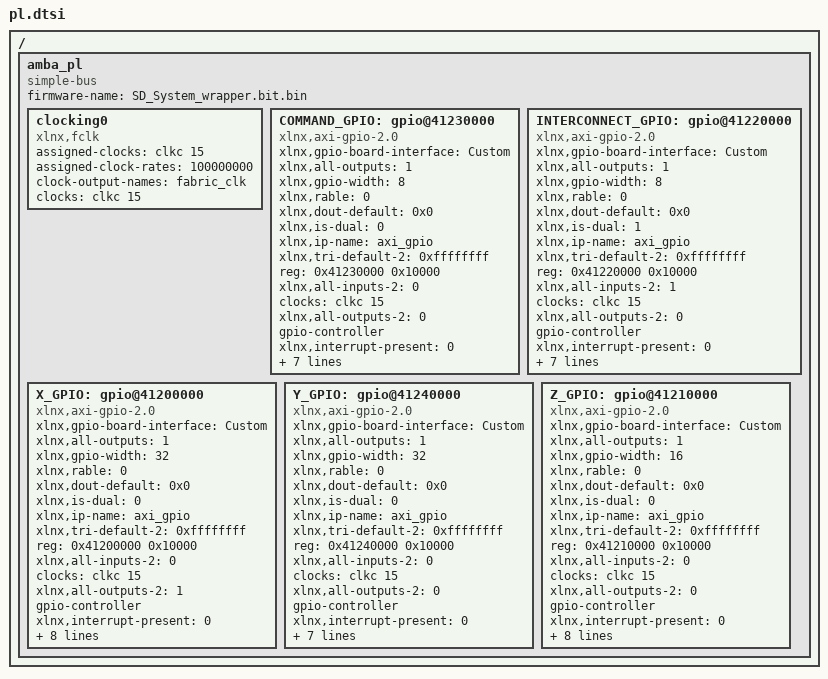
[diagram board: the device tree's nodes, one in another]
/ {
	amba_pl: amba_pl {
		ranges;
		compatible = "simple-bus";
		#address-cells = <1>;
		#size-cells = <1>;
		firmware-name = "SD_System_wrapper.bit.bin";
		clocking0: clocking0 {
			compatible = "xlnx,fclk";
			assigned-clocks = <&clkc 15>;
			assigned-clock-rates = <100000000>;
			#clock-cells = <0>;
			clock-output-names = "fabric_clk";
			clocks = <&clkc 15>;
		};
		COMMAND_GPIO: gpio@41230000 {
			xlnx,gpio-board-interface = "Custom";
			compatible = "xlnx,axi-gpio-2.0" , "xlnx,xps-gpio-1.00.a";
			xlnx,all-outputs = <1>;
			#gpio-cells = <2>;
			xlnx,gpio-width = <8>;
			xlnx,rable = <0>;
			xlnx,dout-default = <0x0>;
			xlnx,is-dual = <0>;
			xlnx,ip-name = "axi_gpio";
			xlnx,tri-default-2 = <0xffffffff>;
			reg = <0x41230000 0x10000>;
			xlnx,all-inputs-2 = <0>;
			clocks = <&clkc 15>;
			xlnx,all-outputs-2 = <0>;
			gpio-controller;
			xlnx,interrupt-present = <0>;
			xlnx,gpio2-board-interface = "Custom";
			xlnx,edk-iptype = "PERIPHERAL";
			xlnx,dout-default-2 = <0x0>;
			status = "okay";
			xlnx,gpio2-width = <32>;
			clock-names = "s_axi_aclk";
			xlnx,tri-default = <0xffffffff>;
			xlnx,name = "COMMAND_GPIO";
			xlnx,all-inputs = <0>;
		};
		INTERCONNECT_GPIO: gpio@41220000 {
			xlnx,gpio-board-interface = "Custom";
			compatible = "xlnx,axi-gpio-2.0" , "xlnx,xps-gpio-1.00.a";
			xlnx,all-outputs = <1>;
			#gpio-cells = <2>;
			xlnx,gpio-width = <8>;
			xlnx,rable = <0>;
			xlnx,dout-default = <0x0>;
			xlnx,is-dual = <1>;
			xlnx,ip-name = "axi_gpio";
			xlnx,tri-default-2 = <0xffffffff>;
			reg = <0x41220000 0x10000>;
			xlnx,all-inputs-2 = <1>;
			clocks = <&clkc 15>;
			xlnx,all-outputs-2 = <0>;
			gpio-controller;
			xlnx,interrupt-present = <0>;
			xlnx,gpio2-board-interface = "Custom";
			xlnx,edk-iptype = "PERIPHERAL";
			xlnx,dout-default-2 = <0x0>;
			status = "okay";
			xlnx,gpio2-width = <8>;
			clock-names = "s_axi_aclk";
			xlnx,tri-default = <0xffffffff>;
			xlnx,name = "INTERCONNECT_GPIO";
			xlnx,all-inputs = <0>;
		};
		X_GPIO: gpio@41200000 {
			xlnx,gpio-board-interface = "Custom";
			compatible = "xlnx,axi-gpio-2.0" , "xlnx,xps-gpio-1.00.a";
			xlnx,all-outputs = <1>;
			#gpio-cells = <2>;
			xlnx,gpio-width = <32>;
			xlnx,rable = <0>;
			xlnx,dout-default = <0x0>;
			xlnx,is-dual = <0>;
			xlnx,ip-name = "axi_gpio";
			xlnx,tri-default-2 = <0xffffffff>;
			reg = <0x41200000 0x10000>;
			xlnx,all-inputs-2 = <0>;
			clocks = <&clkc 15>;
			xlnx,all-outputs-2 = <1>;
			gpio-controller;
			xlnx,interrupt-present = <0>;
			xlnx,gpio2-board-interface = "Custom";
			xlnx,edk-iptype = "PERIPHERAL";
			xlnx,dout-default-2 = <0x0>;
			status = "okay";
			xlnx,gpio2-width = <32>;
			clock-names = "s_axi_aclk";
			xlnx,use-board-flow;
			xlnx,tri-default = <0xffffffff>;
			xlnx,name = "X_GPIO";
			xlnx,all-inputs = <0>;
		};
		Y_GPIO: gpio@41240000 {
			xlnx,gpio-board-interface = "Custom";
			compatible = "xlnx,axi-gpio-2.0" , "xlnx,xps-gpio-1.00.a";
			xlnx,all-outputs = <1>;
			#gpio-cells = <2>;
			xlnx,gpio-width = <32>;
			xlnx,rable = <0>;
			xlnx,dout-default = <0x0>;
			xlnx,is-dual = <0>;
			xlnx,ip-name = "axi_gpio";
			xlnx,tri-default-2 = <0xffffffff>;
			reg = <0x41240000 0x10000>;
			xlnx,all-inputs-2 = <0>;
			clocks = <&clkc 15>;
			xlnx,all-outputs-2 = <0>;
			gpio-controller;
			xlnx,interrupt-present = <0>;
			xlnx,gpio2-board-interface = "Custom";
			xlnx,edk-iptype = "PERIPHERAL";
			xlnx,dout-default-2 = <0x0>;
			status = "okay";
			xlnx,gpio2-width = <32>;
			clock-names = "s_axi_aclk";
			xlnx,tri-default = <0xffffffff>;
			xlnx,name = "Y_GPIO";
			xlnx,all-inputs = <0>;
		};
		Z_GPIO: gpio@41210000 {
			xlnx,gpio-board-interface = "Custom";
			compatible = "xlnx,axi-gpio-2.0" , "xlnx,xps-gpio-1.00.a";
			xlnx,all-outputs = <1>;
			#gpio-cells = <2>;
			xlnx,gpio-width = <16>;
			xlnx,rable = <0>;
			xlnx,dout-default = <0x0>;
			xlnx,is-dual = <0>;
			xlnx,ip-name = "axi_gpio";
			xlnx,tri-default-2 = <0xffffffff>;
			reg = <0x41210000 0x10000>;
			xlnx,all-inputs-2 = <0>;
			clocks = <&clkc 15>;
			xlnx,all-outputs-2 = <0>;
			gpio-controller;
			xlnx,interrupt-present = <0>;
			xlnx,gpio2-board-interface = "Custom";
			xlnx,edk-iptype = "PERIPHERAL";
			xlnx,dout-default-2 = <0x0>;
			status = "okay";
			xlnx,gpio2-width = <32>;
			clock-names = "s_axi_aclk";
			xlnx,use-board-flow;
			xlnx,tri-default = <0xffffffff>;
			xlnx,name = "Z_GPIO";
			xlnx,all-inputs = <0>;
		};
	};
};
